# CY8C5888LTI_LP097 register map
File version: 0.1
CY8C58LP
Registers are 8-bit, read-write, no defined reset value unless marked. A register's access mark holds for its fields unless they carry their own. Offsets are from the block's base; lines under a group give offsets from that group; [hi:lo] are bit positions; {n}, {i} and the like mark numbered series; 'fields as' and 'values as' point back to an identical list; <NAME> marks a mode.

## Memory map
0x00000000 screen — UART
0x00000000 PRINTER_A — UART

## screen — UART
Base 0x00000000
0x40006447 TX_screen_TX_DATA — TX Data Register
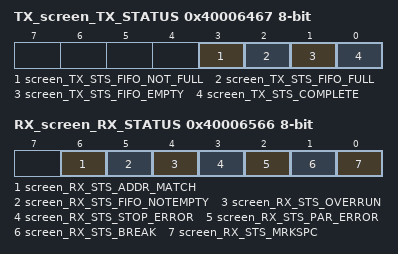
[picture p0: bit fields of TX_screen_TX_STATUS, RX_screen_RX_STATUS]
0x40006467 TX_screen_TX_STATUS — TX status register
  [3] screen_TX_STS_FIFO_NOT_FULL ro, [2] screen_TX_STS_FIFO_FULL ro, [1] screen_TX_STS_FIFO_EMPTY ro, [0] screen_TX_STS_COMPLETE ro
0x40006526 RX_screen_RX_ADDRESS1 — RX Address1 Register
0x40006536 RX_screen_RX_ADDRESS2 — RX Address2 Register
0x40006546 RX_screen_RX_DATA — RX Data Register
0x40006566 RX_screen_RX_STATUS — RX status register
  [6] screen_RX_STS_ADDR_MATCH ro, [5] screen_RX_STS_FIFO_NOTEMPTY ro, [4] screen_RX_STS_OVERRUN ro, [3] screen_RX_STS_STOP_ERROR ro, [2] screen_RX_STS_PAR_ERROR ro, [1] screen_RX_STS_BREAK ro, [0] screen_RX_STS_MRKSPC ro

## PRINTER_A — UART
Base 0x00000000
0x40006544 TX_PRINTER_A_TX_DATA — TX Data Register
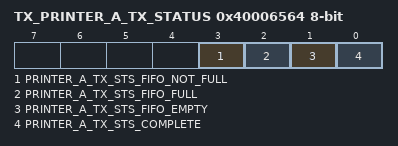
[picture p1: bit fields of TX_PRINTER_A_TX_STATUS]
0x40006564 TX_PRINTER_A_TX_STATUS — TX status register
  [3] PRINTER_A_TX_STS_FIFO_NOT_FULL ro, [2] PRINTER_A_TX_STS_FIFO_FULL ro, [1] PRINTER_A_TX_STS_FIFO_EMPTY ro, [0] PRINTER_A_TX_STS_COMPLETE ro
